# G32R502 register map
Vendor: Geehy Semiconductor Co., Ltd.; Series: G32R5; File version: 1.0
CPU: CM52 r0p1, little endian, MPU, FPU, DSP, VTOR, 4 interrupt priority bits
Registers are 32-bit, read-write, reset 0x0 unless marked. A register's access mark holds for its fields unless they carry their own. Offsets are from the block's base; [hi:lo] are bit positions; {n}, {i} and the like mark numbered series.

## DMA — Direct Memory Access (DMA)
Base 0x40018400
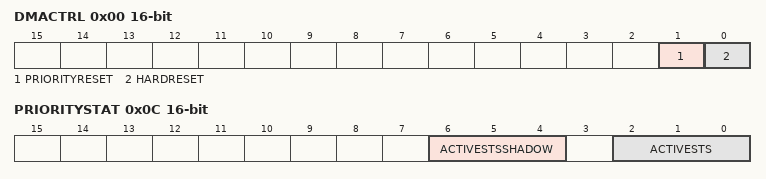
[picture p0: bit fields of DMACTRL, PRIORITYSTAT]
0x00 DMACTRL 16-bit — DMA Control Register
  [1] PRIORITYRESET — Priority Reset Bit
  [0] HARDRESET — Hard Reset Bit
0x02 DEBUGCTRL 16-bit — Debug Control Register
  [15] FREE — Debug Mode Bit
0x08 PRIORITYCTRL1 16-bit — Priority Control 1 Register
  [0] CH1PRIORITY — Ch1 Priority Bit
0x0C PRIORITYSTAT 16-bit — Priority Status Register
  [6:4] ACTIVESTSSHADOW — Active Channel Status Shadow Bits
  [2:0] ACTIVESTS — Active Channel Status Bits

## DMA_CH1 — DMA_CH_REGS
Base 0x40018440
Same registers: DMA_CH2 0x40018480, DMA_CH3 0x400184C0, DMA_CH4 0x40018500, DMA_CH5 0x40018540, DMA_CH6 0x40018580
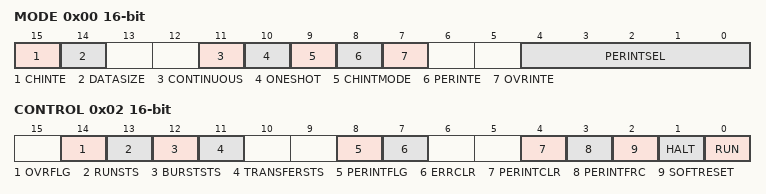
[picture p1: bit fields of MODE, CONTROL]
0x00 MODE 16-bit
  [15] CHINTE — Channel Interrupt Enable Bit
  [14] DATASIZE — Data Size Mode Bit
  [11] CONTINUOUS — Continuous Mode Bit
  [10] ONESHOT — One Shot Mode Bit
  [9] CHINTMODE — Channel Interrupt Mode
  [8] PERINTE — Peripheral Interrupt Enable
  [7] OVRINTE — Overflow Interrupt Enable
  [4:0] PERINTSEL — Peripheral Interrupt and Sync Select
0x02 CONTROL 16-bit
  [14] OVRFLG — Overflow Flag Bit
  [13] RUNSTS — Run Status Bit
  [12] BURSTSTS — Burst Status Bit
  [11] TRANSFERSTS — Transfer Status Bit
  [8] PERINTFLG — Interrupt Flag Bit
  [7] ERRCLR — Error Clear Bit
  [4] PERINTCLR — Interrupt Clear Bit
  [3] PERINTFRC — Interrupt Force Bit
  [2] SOFTRESET — Soft Reset Bit
  [1] HALT — Halt Bit
  [0] RUN — Run Bit
0x04 BURST_SIZE 16-bit
  [4:0] BURSTSIZE — Burst Transfer Size
0x06 BURST_COUNT 16-bit
  [4:0] BURSTCOUNT — Burst Transfer Size
0x08 SRC_BURST_STEP 16-bit — Source Burst Step Register
  [15:0] SRCBURSTSTEP — Source Burst Step
0x0A DST_BURST_STEP 16-bit — Destination Burst Step Register
  [15:0] DSTBURSTSTEP — Destination Burst Step
0x0C TRANSFER_SIZE 16-bit
  [15:0] TRANSFERSIZE
0x0E TRANSFER_COUNT 16-bit
  [15:0] TRANSFERCOUNT
0x10 SRC_TRANSFER_STEP 16-bit — Source Transfer Step Register
  [15:0] SRCTRANSFERSTEP — Source Transfer Step
0x12 DST_TRANSFER_STEP 16-bit — Destination Transfer Step Register
  [15:0] DSTTRANSFERSTEP — Destination Transfer Step
0x14 SRC_WRAP_SIZE 16-bit reset 0xFFFF — Source Wrap Size Register
  [15:0] WRAPSIZE — Source Wrap Size
0x16 SRC_WRAP_COUNT 16-bit — Source Wrap Count Register
  [15:0] WRAPSIZE — Source Wrap Count
0x18 SRC_WRAP_STEP 16-bit — Source Wrap Step Register
  [15:0] WRAPSTEP — Source Transfer Step
0x1A DST_WRAP_SIZE 16-bit reset 0xFFFF — Destination Wrap Size Register
  [15:0] WRAPSIZE — Destination Wrap Size
0x1C DST_WRAP_COUNT 16-bit — Destination Wrap Count Register
  [15:0] WRAPSIZE — Destination Wrap Count
0x1E DST_WRAP_STEP 16-bit — Destination Wrap Step Register
  [15:0] WRAPSTEP — Destination Transfer Step
0x20 SRC_BEG_ADDR_SHADOW — Source Begin Address Shadow Register
  [31:0] BEGADDR — Shadow Source Beginning Address
0x24 SRC_ADDR_SHADOW — Source Address Shadow Register
  [31:0] ADDR — Shadow Source Address
0x28 SRC_BEG_ADDR_ACTIVE — Source Begin Address Active Register
  [31:0] BEGADDR — Active Source Beginning Address
0x2C SRC_ADDR_ACTIVE — Source Address Active Register
  [31:0] ADDR — Active Source Address
0x30 DST_BEG_ADDR_SHADOW — Destination Begin Address Shadow Register
  [31:0] BEGADDR — Shadow Destination Beginning Address
0x34 DST_ADDR_SHADOW — Destination Address Shadow Register
  [31:0] ADDR — Shadow Destination Address
0x38 DST_BEG_ADDR_ACTIVE — Destination Begin Address Active Register
  [31:0] BEGADDR — Active Destination Beginning Address
0x3C DST_ADDR_ACTIVE — Destination Address Active Register
  [31:0] ADDR — Active Destination Address

## PWM_SYNC_SOC
Base 0x40030C80
0x00 SYNCSELECT0 reset 0xE003FFFF
  [28:24] SYNCOUT — Sync Output Source Select
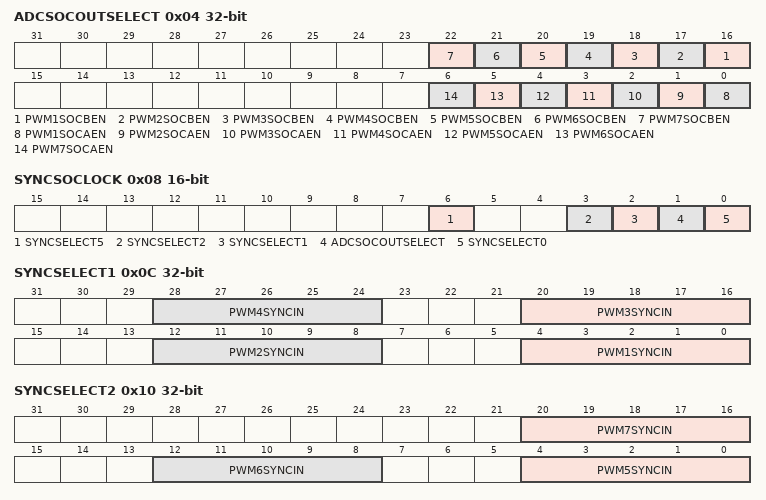
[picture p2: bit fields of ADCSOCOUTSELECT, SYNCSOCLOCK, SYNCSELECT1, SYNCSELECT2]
0x04 ADCSOCOUTSELECT
  [n+15] PWM{n}SOCBEN (n=1..7) — PWM{n} SOCB Output Source Select
  [n-1] PWM{n}SOCAEN (n=1..7) — PWM{n} SOCA Output Source Select
0x08 SYNCSOCLOCK 16-bit
  [6] SYNCSELECT5 — SIOSEL5 Lock
  [3] SYNCSELECT2 — SIOSEL2 Lock
  [2] SYNCSELECT1 — SIOSEL1 Lock
  [1] ADCSOCOUTSELECT — ADCSOCSEL Lock
  [0] SYNCSELECT0 — SIOSEL0 Lock
0x0C SYNCSELECT1
  [8n-4:8n-8] PWM{n}SYNCIN (n=1..4) — PWM{n} Sync Input Source Select
0x10 SYNCSELECT2
  [20:16] PWM7SYNCIN — PWM7 Sync Input Source Select
  [12:8] PWM6SYNCIN — PWM6 Sync Input Source Select
  [4:0] PWM5SYNCIN — PWM5 Sync Input Source Select
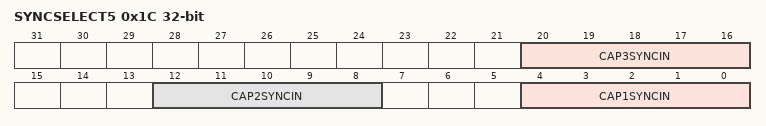
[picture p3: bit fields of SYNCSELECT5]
0x1C SYNCSELECT5
  [20:16] CAP3SYNCIN — CAP3 Sync Input Source Select
  [12:8] CAP2SYNCIN — CAP2 Sync Input Source Select
  [4:0] CAP1SYNCIN — CAP1 Sync Input Source Select
